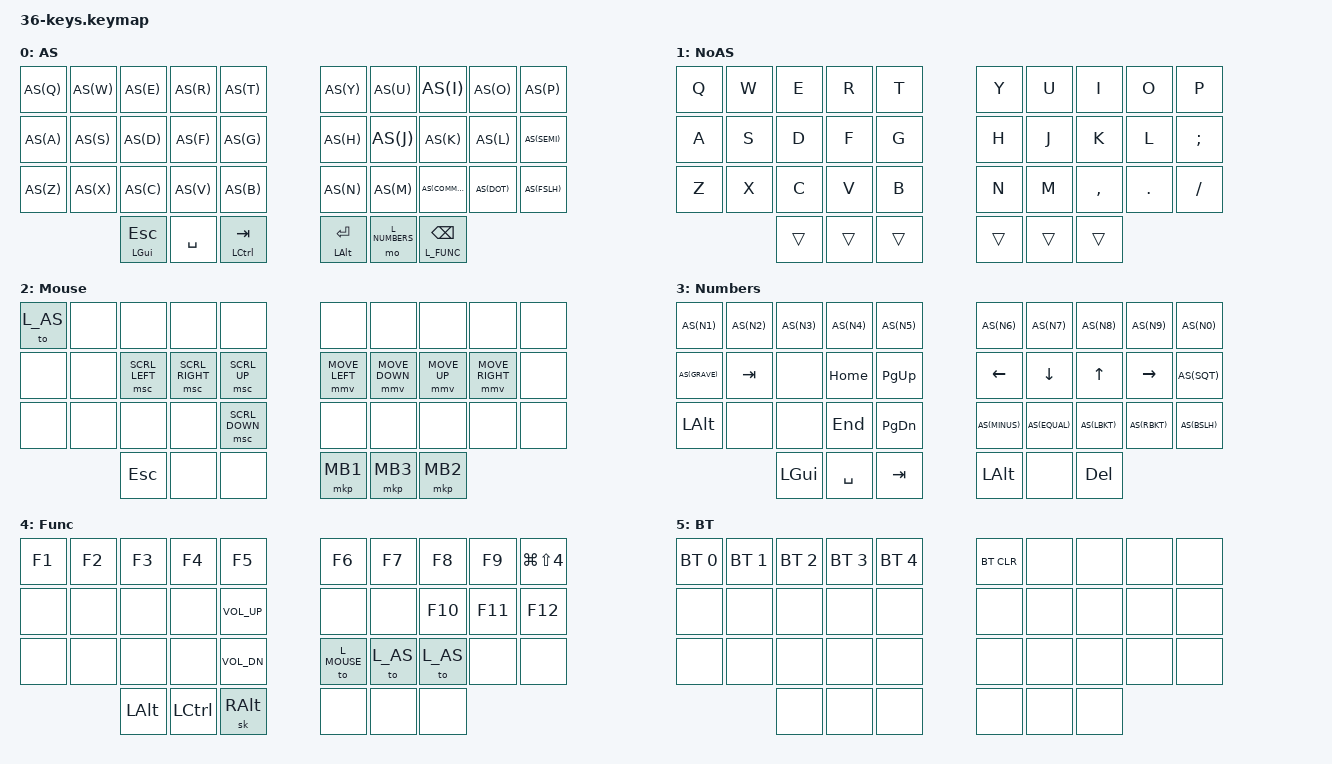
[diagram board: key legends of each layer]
/*
 * Copyright (c) 2024 The ZMK Contributors
 *
 * SPDX-License-Identifier: MIT
 */

#include <behaviors.dtsi>
#include <dt-bindings/zmk/bt.h>
#include <dt-bindings/zmk/keys.h>
#include <dt-bindings/zmk/pointing.h>

#define L_AS 0
#define L_NO_AS 1
#define L_MOUSE 2
#define L_NUMBERS 3
#define L_FUNC 4
#define L_BT 5

#define AS(keycode) &as LS(keycode) keycode

#define TK30 &mt LGUI ESC
#define TK31 &kp SPC
#define TK32 &mt LCTRL TAB
#define TK33 &mt LALT ENTER
#define TK34 &mo L_NUMBERS
#define TK35 &lt L_FUNC BSPC


&caps_word {
    continue-list = <UNDERSCORE MINUS BSPC>;
};

/*                KEY POSITIONS
  ╭────────────────────╮ ╭────────────────────╮
  │  0   1   2   3   4 │ │  5   6   7   8   9 │
  │ 10  11  12  13  14 │ │ 15  16  17  18  19 │
  │ 20  21  22  23  24 │ │ 25  26  27  28  29 │
  ╰───────╮ 30  31  32 │ │ 33  34  35 ╭───────╯
          ╰────────────╯ ╰────────────╯        */

/ {
    combos {
        compatible = "zmk,combos";
        combo_bt {
            key-positions = <9 19 29>;
            bindings = <&mo L_BT>;
        };
        combo_caps_word {
            key-positions = <30 35>;
            bindings = <&caps_word>;
        };
        combo_meh {
            key-positions = <32 33>;
            bindings = <&kp LS(LC(LALT))>;
        };
        combo_lshift {
            key-positions = <20 21>;
            bindings = <&sk LSHIFT>;
            slow-release;
        };
        combo_rshift {
            key-positions = <28 29>;
            bindings = <&sk RSHIFT>;
            slow-release;
        };
        combo_laltgr {
            key-positions = <0 1>;
            bindings = <&sk RALT>;
            slow-release;
        };
        combo_raltgr {
            key-positions = <8 9>;
            bindings = <&sk RALT>;
            slow-release;
        };
    };

    behaviors {
        as: auto_shift {
            compatible = "zmk,behavior-hold-tap";
            display-name = "AUTO_SHIFT";
            #binding-cells = <2>;
            tapping-term-ms = <200>;
            quick-tap-ms = <0>;
            flavor = "tap-preferred";
            bindings = <&kp>, <&kp>;
        };
    };

    keymap {
        compatible = "zmk,keymap";
        default_layer {
            display-name = "AS";
            bindings = <
    AS(Q) AS(W) AS(E) AS(R) AS(T)       AS(Y) AS(U)  AS(I)     AS(O)   AS(P)
    AS(A) AS(S) AS(D) AS(F) AS(G)       AS(H) AS(J)  AS(K)     AS(L)   AS(SEMI)
    AS(Z) AS(X) AS(C) AS(V) AS(B)       AS(N) AS(M)  AS(COMMA) AS(DOT) AS(FSLH)
                TK30  TK31  TK32        TK33  TK34   TK35
            >;
        };
        no_auto_shift {
            display-name = "NoAS";
            bindings = <
    &kp Q &kp W &kp E  &kp R  &kp T        &kp Y &kp U  &kp I     &kp O   &kp P
    &kp A &kp S &kp D  &kp F  &kp G        &kp H &kp J  &kp K     &kp L   &kp SEMI
    &kp Z &kp X &kp C  &kp V  &kp B        &kp N &kp M  &kp COMMA &kp DOT &kp FSLH
                &trans &trans &trans       &trans &trans &trans
            >;
        };
        mouse {
            display-name = "Mouse";
            bindings = <
    &to L_AS &none &none          &none           &none             &none          &none          &none        &none           &none
    &none    &none &msc SCRL_LEFT &msc SCRL_RIGHT &msc SCRL_UP      &mmv MOVE_LEFT &mmv MOVE_DOWN &mmv MOVE_UP &mmv MOVE_RIGHT &none
    &none    &none &none          &none           &msc SCRL_DOWN    &none          &none          &none        &none           &none
             &kp ESC              &none           &none             &mkp MB1       &mkp MB3       &mkp MB2
            >;
        };
        num_layer {
            display-name = "Numbers";
            bindings = <
    AS(N1)    AS(N2)  AS(N3)     AS(N4)   AS(N5)         AS(N6)    AS(N7)    AS(N8)   AS(N9)    AS(N0)
    AS(GRAVE) &kp TAB &none      &kp HOME &kp PG_UP      &kp LEFT  &kp DOWN  &kp UP   &kp RIGHT AS(SQT)
    &kp LALT  &none   &none      &kp END  &kp PG_DN      AS(MINUS) AS(EQUAL) AS(LBKT) AS(RBKT)  AS(BSLH)
                      &kp LGUI   &kp SPC  &kp TAB        &kp LALT  &none     &kp DEL
            >;
        };
        function_layer {
            display-name = "Func";
            bindings = <
    &kp F1 &kp F2 &kp F3   &kp F4    &kp F5            &kp F6   &kp F7      &kp F8     &kp F9  &kp LG(LS(N4))
    &none  &none  &none    &none     &kp C_VOL_UP      &none    &none       &kp F10    &kp F11 &kp F12
    &none  &none  &none    &none     &kp C_VOL_DN      &to L_MOUSE &to L_AS &to L_AS &none   &none
                  &kp LALT &kp LCTRL &sk RALT          &none       &none    &none
            >;
        };
        bt_layer {
            display-name = "BT";
            bindings = <
    &bt BT_SEL 0 &bt BT_SEL 1 &bt BT_SEL 2 &bt BT_SEL 3 &bt BT_SEL 4 &bt BT_CLR  &none &none &none &none
    &none        &none        &none        &none        &none        &none &none &none &none &none
    &none        &none        &none        &none        &none        &none &none &none &none &none
                              &none        &none        &none        &none &none &none
            >;
        };
	};
};
